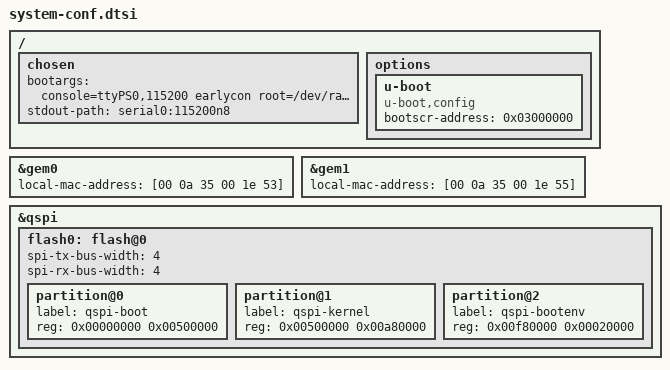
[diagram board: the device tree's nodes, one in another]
/*
 * CAUTION: This file is automatically generated by PetaLinux SDK.
 * DO NOT modify this file
 */


/ {
	chosen {
		bootargs = "console=ttyPS0,115200 earlycon root=/dev/ram0 rw";
		stdout-path = "serial0:115200n8";
	};

	options {
		u-boot {
			compatible = "u-boot,config";
			bootscr-address = /bits/ 64 <0x03000000>;
		};
	};
};

&gem0 {
	local-mac-address = [00 0a 35 00 1e 53];
};

&gem1 {
	local-mac-address = [00 0a 35 00 1e 55];
};

&qspi {
	#address-cells = <1>;
	#size-cells = <0>;
	flash0: flash@0 {
		spi-tx-bus-width=<4>;
		spi-rx-bus-width=<4>;
		/delete-node/ partition@0;
		/delete-node/ partition@100000;
		/delete-node/ partition@600000;
		/delete-node/ partition@620000;
		/delete-node/ partition@c00000;
		partition@0 {
			label = "qspi-boot";
			reg = <0x00000000 0x00500000>;
		};
		partition@1 {
			label = "qspi-kernel";
			reg = <0x00500000 0x00a80000>;
		};
		partition@2 {
			label = "qspi-bootenv";
			reg = <0x00f80000 0x00020000>;
		};
	};
};

